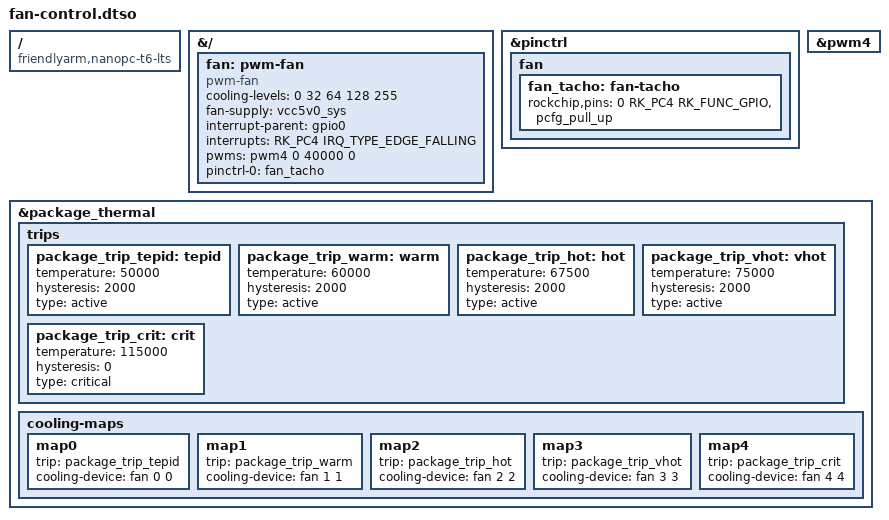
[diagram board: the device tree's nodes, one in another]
/dts-v1/;
/plugin/;

#include <dt-bindings/interrupt-controller/irq.h>
#include <dt-bindings/pinctrl/rockchip.h>

/ {
	compatible = "friendlyarm,nanopc-t6-lts";
};

&{/} {
	fan: pwm-fan {
		compatible = "pwm-fan";
		cooling-levels = <0 32 64 128 255>;
		fan-supply = <&vcc5v0_sys>;
		interrupt-parent = <&gpio0>;
		interrupts = <RK_PC4 IRQ_TYPE_EDGE_FALLING>;
		pwms = <&pwm4 0 40000 0>; /* 25 kHz -> 40000 ns */
		pinctrl-names = "default";
		pinctrl-0 = <&fan_tacho>;
		#cooling-cells = <2>;
	};
};

&pinctrl {
	fan {
		fan_tacho: fan-tacho {
			rockchip,pins = <0 RK_PC4 RK_FUNC_GPIO &pcfg_pull_up>;
		};
	};
};

&pwm4 {
	status = "okay";
};

&package_thermal {
	trips {
		package_trip_tepid: tepid {
			temperature = <50000>;
			hysteresis = <2000>;
			type = "active";
		};

		package_trip_warm: warm {
			temperature = <60000>;
			hysteresis = <2000>;
			type = "active";
		};

		package_trip_hot: hot {
			temperature = <67500>;
			hysteresis = <2000>;
			type = "active";
		};

		package_trip_vhot: vhot {
			temperature = <75000>;
			hysteresis = <2000>;
			type = "active";
		};

		package_trip_crit: crit {
			temperature = <115000>;
			hysteresis = <0>;
			type = "critical";
		};
	};

	cooling-maps {
		map0 {
			trip = <&package_trip_tepid>;
			cooling-device = <&fan 0 0>;
		};

		map1 {
			trip = <&package_trip_warm>;
			cooling-device = <&fan 1 1>;
		};

		map2 {
			trip = <&package_trip_hot>;
			cooling-device = <&fan 2 2>;
		};

		map3 {
			trip = <&package_trip_vhot>;
			cooling-device = <&fan 3 3>;
		};

		map4 {
			trip = <&package_trip_crit>;
			cooling-device = <&fan 4 4>;
		};
	};
};
